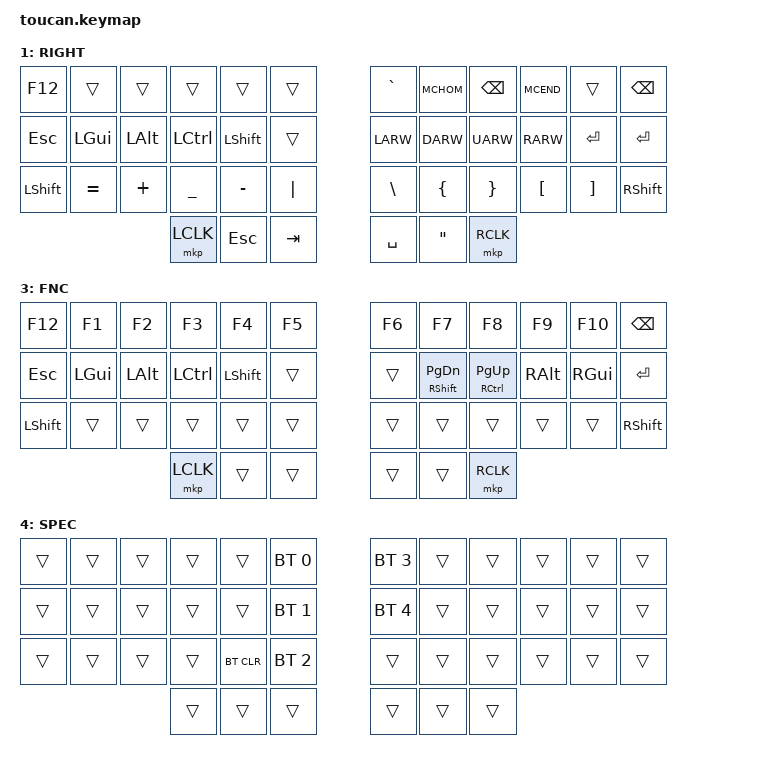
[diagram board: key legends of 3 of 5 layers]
#include <behaviors.dtsi>
#include <dt-bindings/zmk/keys.h>
#include <dt-bindings/zmk/bt.h>
#include <dt-bindings/zmk/outputs.h>
#include <dt-bindings/zmk/pointing.h>

#define BASE 0
#define RGHT 1
#define LFT 2
#define FNC 3
#define SPEC 4

// Home row mods macro
#define HRML(k1,k2,k3,k4) &ht LGUI k1   &ht LALT k2   &ht LCTRL k3  &ht LSHFT k4
#define HRMR(k1,k2,k3,k4) &ht RSHFT k1  &ht RCTRL k2  &ht RALT k3   &ht RGUI k4
#define MCHOM LG(LARW)
#define MCEND LG(RARW)

/ {
    behaviors {
        ht: hold_tap {
            compatible = "zmk,behavior-hold-tap";
            #binding-cells = <2>;
            flavor = "balanced";
            tapping-term-ms = <220>;
            quick-tap-ms = <150>;
            require-prior-idle-ms = <125>;
            bindings = <&kp>, <&kp>;
        };
    };

    //conditional_layers {
    //    compatible = "zmk,conditional-layers";
    //    tri_layer {
    //        if-layers = <1 2>;
    //        then-layer = <3>;
    //    };
    //};

    keymap {
        compatible = "zmk,keymap";

        base {
            display-name = "BASE";
            bindings = <
                &kp F12   &kp Q    &kp W  &kp E  &kp R  &kp T          &kp Y  &kp U    &kp I      &kp O    &kp P     &kp BSPC
                &kp ESC   HRML(A,  S,     D,     F)     &kp G          &kp H  HRMR(J,  K,         L,       SEMI)     &kp ENTER
                &kp LSHFT &lt 4 Z  &kp X  &kp C  &kp V  &kp B          &kp N  &kp M    &kp COMMA  &kp DOT  &kp FSLH  &kp RSHFT
                              &mkp LCLK  &lt 3 ESC  &lt 2 TAB          &lt 1 SPC  &lt 3 SQT  &mkp RCLK
            >;
        };

        rght {
            display-name = "RIGHT";
            bindings = <
                &kp F12   &trans     &trans     &trans     &trans     &trans         &kp GRAVE  &kp MCHOM  &kp BSPC   &kp MCEND  &trans    &kp BSPC
                &kp ESC   &kp LGUI   &kp LALT   &kp LCTRL  &kp LSHFT  &trans         &kp LARW   &kp DARW   &kp UARW   &kp RARW   &kp RET   &kp ENTER
                &kp LSHFT &kp EQUAL  &kp PLUS   &kp UNDER  &kp MINUS  &kp PIPE       &kp BSLH   &kp LBRC   &kp RBRC   &kp LBKT   &kp RBKT  &kp RSHFT
                                                &mkp LCLK  &kp ESC    &kp TAB        &kp SPC    &kp DQT    &mkp RCLK
            >;
        };

        lft {
            display-name = "LEFT";
            bindings = <
                &kp F12   &kp N1     &kp N2     &kp N3     &kp N4     &kp N5         &kp N6     &kp N7     &kp N8     &kp N9     &kp N0    &kp BSPC
                &kp ESC   HRML(EXCL, AT,        HASH,      DLLR)      &kp PRCNT      &kp CARET  HRMR(AMPS, STAR,      LPAR,      RPAR)     &kp ENTER
                &kp LSHFT &kp EQUAL   &kp PLUS  &kp UNDER  &kp MINUS  &kp PIPE       &kp BSLH   &kp LBRC   &kp RBRC   &kp LBKT   &kp RBKT  &kp RSHFT
                                                &mkp LCLK  &kp ESC    &kp TAB        &kp SPC    &kp DQT    &mkp RCLK
            >;
        };

        fnc {
            display-name = "FNC";
            bindings = <
                &kp F12   &kp F1     &kp F2     &kp F3     &kp F4     &kp F5         &kp F6     &kp F7           &kp F8           &kp F9     &kp F10   &kp BSPC
                &kp ESC   &kp LGUI   &kp LALT   &kp LCTRL  &kp LSHFT  &trans         &trans     &mt RSHFT PG_DN  &mt RCTRL PG_UP  &kp RALT   &kp RGUI  &kp ENTER
                &kp LSHFT &trans     &trans     &trans     &trans     &trans         &trans     &trans           &trans           &trans     &trans    &kp RSHFT
                                                &mkp LCLK  &trans     &trans         &trans     &trans           &mkp RCLK
            >;
        };

        spec {
            display-name = "SPEC";
            bindings = <
                &trans  &trans  &trans  &trans  &trans      &bt BT_SEL 0         &bt BT_SEL 3  &trans  &trans  &trans  &trans  &trans
                &trans  &trans  &trans  &trans  &trans      &bt BT_SEL 1         &bt BT_SEL 4  &trans  &trans  &trans  &trans  &trans
                &trans  &trans  &trans  &trans  &bt BT_CLR  &bt BT_SEL 2         &trans        &trans  &trans  &trans  &trans  &trans
                                        &trans  &trans      &trans               &trans        &trans  &trans
            >;
        };

        extra_1 {
                status = "reserved";
        };

        extra_2 {
                status = "reserved";
        };

        extra_3 {
                status = "reserved";
        };
    };
};
